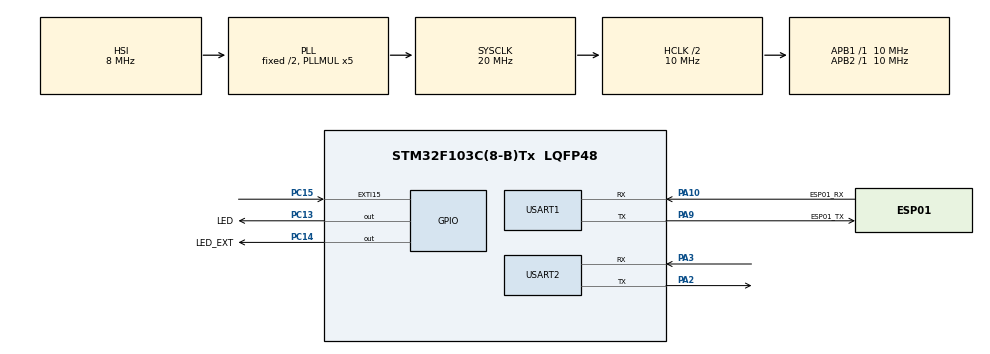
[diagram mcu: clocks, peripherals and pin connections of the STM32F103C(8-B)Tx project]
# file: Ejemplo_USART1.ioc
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Mcu.Family=STM32F1
Mcu.Name=STM32F103C(8-B)Tx
Mcu.Package=LQFP48
NVIC.EXTI15_10_IRQn=true\:0\:0\:false\:false\:true\:true\:true\:true
NVIC.PriorityGroup=NVIC_PRIORITYGROUP_4
NVIC.TIM1_UP_IRQn=true\:0\:0\:false\:false\:true\:true\:true\:true
NVIC.USART2_IRQn=true\:0\:0\:false\:false\:true\:true\:true\:true
PA10.GPIO_Label=ESP01_RX
PA10.Mode=Asynchronous
PA10.Signal=USART1_RX
PA13.Mode=Serial_Wire
PA13.Signal=SYS_JTMS-SWDIO
PA14.Mode=Serial_Wire
PA14.Signal=SYS_JTCK-SWCLK
PA2.Mode=Asynchronous
PA2.Signal=USART2_TX
PA3.Mode=Asynchronous
PA3.Signal=USART2_RX
PA9.GPIO_Label=ESP01_TX
PA9.Mode=Asynchronous
PA9.Signal=USART1_TX
PC13-TAMPER-RTC.GPIO_Label=LED
PC13-TAMPER-RTC.Signal=GPIO_Output
PC14-OSC32_IN.GPIO_Label=LED_EXT
PC14-OSC32_IN.Signal=GPIO_Output
PC15-OSC32_OUT.Signal=GPXTI15
ProjectManager.HeapSize=0x200
ProjectManager.StackSize=0x400
ProjectManager.TargetToolchain=Makefile
RCC.AHBCLKDivider=RCC_SYSCLK_DIV2
RCC.AHBFreq_Value=10000000
RCC.APB1Freq_Value=10000000
RCC.APB1TimFreq_Value=10000000
RCC.APB2Freq_Value=10000000
RCC.APB2TimFreq_Value=10000000
RCC.HCLKFreq_Value=10000000
RCC.PLLMUL=RCC_PLL_MUL5
RCC.SYSCLKFreq_VALUE=20000000
RCC.SYSCLKSource=RCC_SYSCLKSOURCE_PLLCLK
RCC.USBFreq_Value=20000000
TIM1.Period=1000
TIM1.Prescaler=10000
USART1.VirtualMode=VM_ASYNC
USART2.VirtualMode=VM_ASYNC
VP_TIM1_VS_ClockSourceINT.Mode=Internal
board=custom

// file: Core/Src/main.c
/* USER CODE BEGIN Header */
/**
  ******************************************************************************
  * @file           : main.c
  * @brief          : Main program body
  ******************************************************************************
  * @attention
  *
  * Copyright (c) 2022 STMicroelectronics.
  * All rights reserved.
  *
  * This software is licensed under terms that can be found in the LICENSE file
  * in the root directory of this software component.
  * If no LICENSE file comes with this software, it is provided AS-IS.
  *
  ******************************************************************************
  */
/* USER CODE END Header */
#include "main.h"
#include "string.h"
#include "stdio.h"

/* USER CODE BEGIN PD */
#define SIZE 100
char bufferRX[SIZE];
/* USER CODE END PD */

 TIM_HandleTypeDef htim1;

UART_HandleTypeDef huart1;
UART_HandleTypeDef huart2;

void SystemClock_Config(void);
static void MX_GPIO_Init(void);
static void MX_TIM1_Init(void);
static void MX_USART1_UART_Init(void);
static void MX_USART2_UART_Init(void);

int main(void)
{

  /* MCU Configuration--------------------------------------------------------*/

  /* Reset of all peripherals, Initializes the Flash interface and the Systick. */
  HAL_Init();

  /* Configure the system clock */
  SystemClock_Config();

  /* Initialize all configured peripherals */
  MX_GPIO_Init();
  MX_TIM1_Init();
  MX_USART1_UART_Init();
  MX_USART2_UART_Init();
  #define MESSAGE "Hola Mundo \r\n"
  #define ELEMENT_SIZE 1 //(strlen(MESSAGE))
  HAL_UART_Receive_IT(&huart2, (uint8_t*) bufferRX, ELEMENT_SIZE);
  /* Infinite loop */
  while (1)
  {
    //HAL_UART_Transmit(&huart1, (uint8_t*) MESSAGE, strlen (MESSAGE), 1000);
    //HAL_Delay(1000);
    //HAL_UART_Receive(&huart2, (uint8_t*) bufferRX, SIZE, 1000);
  }
}

static uint8_t counter = 0;
static char buff[100];

void HAL_UART_RxCpltCallback(UART_HandleTypeDef *huart) {

  #define END_CMD ('x')
  if (huart->Instance == USART2){
    HAL_GPIO_TogglePin(LED_GPIO_Port, LED_Pin);

    if (bufferRX[counter] == END_CMD){
      #define MESSAGERX "Se recibio el mensaje: %s \r\n"
      bufferRX[counter] = 0;
      sprintf(buff, MESSAGERX, bufferRX);
      HAL_UART_Transmit(huart, (uint8_t*) buff, strlen (buff), 1000);
      counter = 0;
    } else {
      counter++;
    }
    HAL_UART_Receive_IT(huart, (uint8_t*) (bufferRX + counter) , ELEMENT_SIZE);
  }
}

void SystemClock_Config(void)
{
  RCC_OscInitTypeDef RCC_OscInitStruct = {0};
  RCC_ClkInitTypeDef RCC_ClkInitStruct = {0};

  /** Initializes the RCC Oscillators according to the specified parameters
  * in the RCC_OscInitTypeDef structure.
  */
  RCC_OscInitStruct.OscillatorType = RCC_OSCILLATORTYPE_HSI;
  RCC_OscInitStruct.HSIState = RCC_HSI_ON;
  RCC_OscInitStruct.HSICalibrationValue = RCC_HSICALIBRATION_DEFAULT;
  RCC_OscInitStruct.PLL.PLLState = RCC_PLL_ON;
  RCC_OscInitStruct.PLL.PLLSource = RCC_PLLSOURCE_HSI_DIV2;
  RCC_OscInitStruct.PLL.PLLMUL = RCC_PLL_MUL5;
  if (HAL_RCC_OscConfig(&RCC_OscInitStruct) != HAL_OK)
  {
    Error_Handler();
  }

  /** Initializes the CPU, AHB and APB buses clocks
  */
  RCC_ClkInitStruct.ClockType = RCC_CLOCKTYPE_HCLK|RCC_CLOCKTYPE_SYSCLK
                              |RCC_CLOCKTYPE_PCLK1|RCC_CLOCKTYPE_PCLK2;
  RCC_ClkInitStruct.SYSCLKSource = RCC_SYSCLKSOURCE_PLLCLK;
  RCC_ClkInitStruct.AHBCLKDivider = RCC_SYSCLK_DIV2;
  RCC_ClkInitStruct.APB1CLKDivider = RCC_HCLK_DIV1;
  RCC_ClkInitStruct.APB2CLKDivider = RCC_HCLK_DIV1;

  if (HAL_RCC_ClockConfig(&RCC_ClkInitStruct, FLASH_LATENCY_0) != HAL_OK)
  {
    Error_Handler();
  }
}

static void MX_TIM1_Init(void)
{

  TIM_ClockConfigTypeDef sClockSourceConfig = {0};
  TIM_MasterConfigTypeDef sMasterConfig = {0};

  htim1.Instance = TIM1;
  htim1.Init.Prescaler = 10000;
  htim1.Init.CounterMode = TIM_COUNTERMODE_UP;
  htim1.Init.Period = 1000;
  htim1.Init.ClockDivision = TIM_CLOCKDIVISION_DIV1;
  htim1.Init.RepetitionCounter = 0;
  htim1.Init.AutoReloadPreload = TIM_AUTORELOAD_PRELOAD_DISABLE;
  if (HAL_TIM_Base_Init(&htim1) != HAL_OK)
  {
    Error_Handler();
  }
  sClockSourceConfig.ClockSource = TIM_CLOCKSOURCE_INTERNAL;
  if (HAL_TIM_ConfigClockSource(&htim1, &sClockSourceConfig) != HAL_OK)
  {
    Error_Handler();
  }
  sMasterConfig.MasterOutputTrigger = TIM_TRGO_RESET;
  sMasterConfig.MasterSlaveMode = TIM_MASTERSLAVEMODE_DISABLE;
  if (HAL_TIMEx_MasterConfigSynchronization(&htim1, &sMasterConfig) != HAL_OK)
  {
    Error_Handler();
  }

}

static void MX_USART1_UART_Init(void)
{

  huart1.Instance = USART1;
  huart1.Init.BaudRate = 115200;
  huart1.Init.WordLength = UART_WORDLENGTH_8B;
  huart1.Init.StopBits = UART_STOPBITS_1;
  huart1.Init.Parity = UART_PARITY_NONE;
  huart1.Init.Mode = UART_MODE_TX_RX;
  huart1.Init.HwFlowCtl = UART_HWCONTROL_NONE;
  huart1.Init.OverSampling = UART_OVERSAMPLING_16;
  if (HAL_UART_Init(&huart1) != HAL_OK)
  {
    Error_Handler();
  }

}

static void MX_USART2_UART_Init(void)
{

  huart2.Instance = USART2;
  huart2.Init.BaudRate = 115200;
  huart2.Init.WordLength = UART_WORDLENGTH_8B;
  huart2.Init.StopBits = UART_STOPBITS_1;
  huart2.Init.Parity = UART_PARITY_NONE;
  huart2.Init.Mode = UART_MODE_TX_RX;
  huart2.Init.HwFlowCtl = UART_HWCONTROL_NONE;
  huart2.Init.OverSampling = UART_OVERSAMPLING_16;
  if (HAL_UART_Init(&huart2) != HAL_OK)
  {
    Error_Handler();
  }

}

static void MX_GPIO_Init(void)
{
  GPIO_InitTypeDef GPIO_InitStruct = {0};

  /* GPIO Ports Clock Enable */
  __HAL_RCC_GPIOC_CLK_ENABLE();
  __HAL_RCC_GPIOA_CLK_ENABLE();

  /*Configure GPIO pin Output Level */
  HAL_GPIO_WritePin(GPIOC, GPIO_PIN_13|GPIO_PIN_14, GPIO_PIN_RESET);

  /*Configure GPIO pins : PC13 PC14 */
  GPIO_InitStruct.Pin = GPIO_PIN_13|GPIO_PIN_14;
  GPIO_InitStruct.Mode = GPIO_MODE_OUTPUT_PP;
  GPIO_InitStruct.Pull = GPIO_NOPULL;
  GPIO_InitStruct.Speed = GPIO_SPEED_FREQ_LOW;
  HAL_GPIO_Init(GPIOC, &GPIO_InitStruct);

  /*Configure GPIO pin : PC15 */
  GPIO_InitStruct.Pin = GPIO_PIN_15;
  GPIO_InitStruct.Mode = GPIO_MODE_IT_RISING;
  GPIO_InitStruct.Pull = GPIO_NOPULL;
  HAL_GPIO_Init(GPIOC, &GPIO_InitStruct);

  /* EXTI interrupt init*/
  HAL_NVIC_SetPriority(EXTI15_10_IRQn, 0, 0);
  HAL_NVIC_EnableIRQ(EXTI15_10_IRQn);

}

void Error_Handler(void)
{
  __disable_irq();
  while (1)
  {
  }
}
